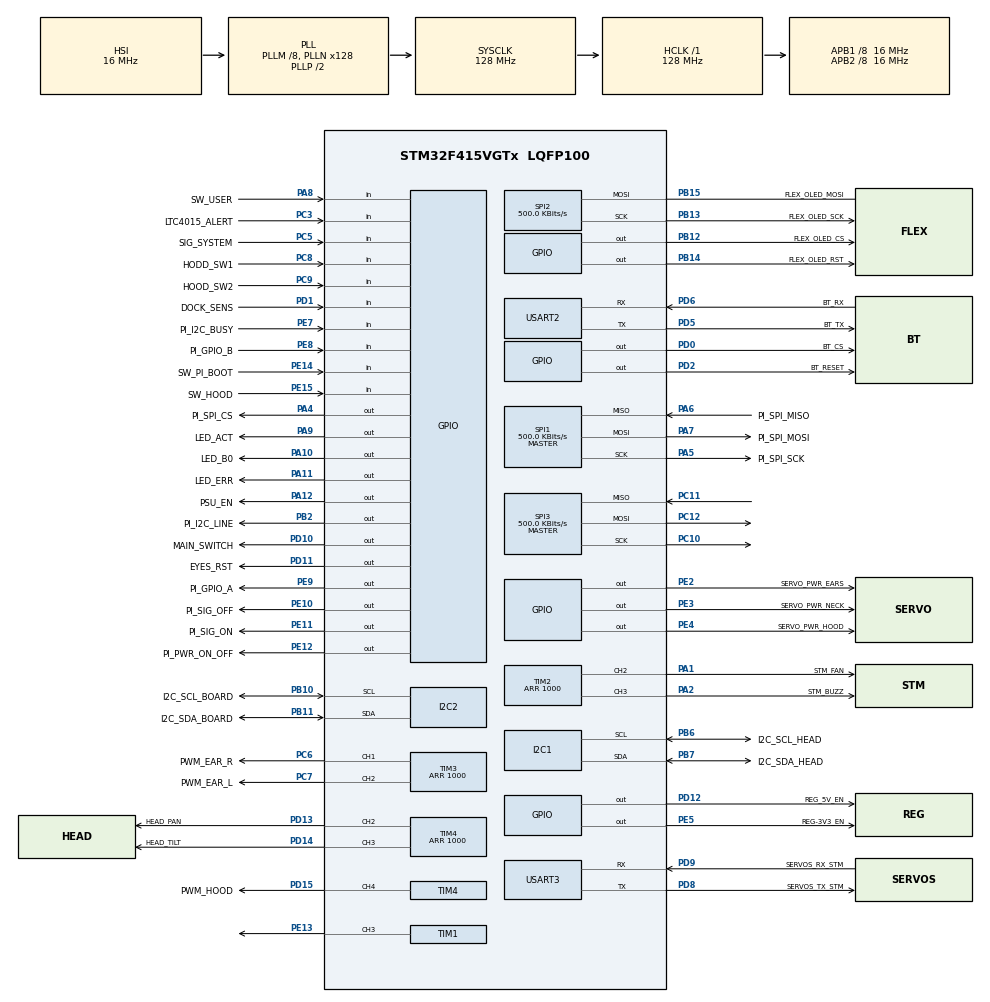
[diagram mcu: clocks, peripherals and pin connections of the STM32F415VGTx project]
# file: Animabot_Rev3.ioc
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FREERTOS.BinarySemaphores01=myBinarySem01;myBinarySem02;myBinarySem03
FREERTOS.Queues01=myQueue01,16,uint16_t,0,Dynamic,NULL,NULL
FREERTOS.Tasks01=Task_Default,0,128,StartTask_Default,Default,NULL,Dynamic,NULL,NULL;Task_Activity,-2,128,StartTask_Activity,Default,NULL,Dynamic,NULL,NULL;Task_System,0,128,StartTask_System,Default,NULL,Dynamic,NULL,NULL;Task_FlexOled,0,128,StartTask_FlexOled,Default,NULL,Dynamic,NULL,NULL;Task_PwrMngt,2,128,StartTask_PwrMngt,Default,NULL,Dynamic,NULL,NULL;Task_Sensors,2,128,StartTask_Sensors,Default,NULL,Dynamic,NULL,NULL;Task_Rpi,2,128,StartTask_Rpi,Default,NULL,Dynamic,NULL,NULL;Task_Bluetooth,0,128,StartTask_Bluetooth,Default,NULL,Dynamic,NULL,NULL;Task_Behavior,2,128,StartTask_Behavior,Default,NULL,Dynamic,NULL,NULL;Task_Kinematic,2,128,StartTask_Kinematic,Default,NULL,Dynamic,NULL,NULL
FREERTOS.configGENERATE_RUN_TIME_STATS=1
FREERTOS.configUSE_STATS_FORMATTING_FUNCTIONS=1
FREERTOS.configUSE_TICKLESS_IDLE=1
FREERTOS.configUSE_TRACE_FACILITY=1
I2C1.I2C_Mode=I2C_Fast
I2C2.I2C_Mode=I2C_Fast
Mcu.Family=STM32F4
Mcu.Name=STM32F415VGTx
Mcu.Package=LQFP100
NVIC.PriorityGroup=NVIC_PRIORITYGROUP_4
NVIC.TIM1_BRK_TIM9_IRQn=true\:0\:0\:false\:false\:true\:false\:true
PA1.GPIO_Label=STM_FAN
PA1.Signal=S_TIM2_CH2
PA10.GPIO_Label=LED_B0
PA10.GPIO_PuPd=GPIO_PULLDOWN
PA10.Signal=GPIO_Output
PA11.GPIO_Label=LED_ERR
PA11.GPIO_PuPd=GPIO_PULLDOWN
PA11.Signal=GPIO_Output
PA12.GPIO_Label=PSU_EN
PA12.GPIO_PuPd=GPIO_PULLDOWN
PA12.Signal=GPIO_Output
PA13.Mode=JTAG_5_pins
PA13.Signal=SYS_JTMS-SWDIO
PA14.Mode=JTAG_5_pins
PA14.Signal=SYS_JTCK-SWCLK
PA15.Mode=JTAG_5_pins
PA15.Signal=SYS_JTDI
PA2.GPIO_Label=STM_BUZZ
PA2.Signal=S_TIM2_CH3
PA4.GPIO_Label=PI_SPI_CS
PA4.Signal=GPIO_Output
PA5.GPIO_Label=PI_SPI_SCK
PA5.Mode=Full_Duplex_Master
PA5.Signal=SPI1_SCK
PA6.GPIO_Label=PI_SPI_MISO
PA6.Mode=Full_Duplex_Master
PA6.Signal=SPI1_MISO
PA7.GPIO_Label=PI_SPI_MOSI
PA7.Mode=Full_Duplex_Master
PA7.Signal=SPI1_MOSI
PA8.GPIO_Label=SW_USER
PA8.Signal=GPIO_Input
PA9.GPIO_Label=LED_ACT
PA9.GPIO_PuPd=GPIO_PULLDOWN
PA9.Signal=GPIO_Output
PB10.GPIO_Label=I2C_SCL_BOARD
PB10.Mode=I2C
PB10.Signal=I2C2_SCL
PB11.GPIO_Label=I2C_SDA_BOARD
PB11.Mode=I2C
PB11.Signal=I2C2_SDA
PB12.GPIO_Label=FLEX_OLED_CS
PB12.Signal=GPIO_Output
PB13.GPIO_Label=FLEX_OLED_SCK
PB13.Mode=Simplex_Bidirectional_Master
PB13.Signal=SPI2_SCK
PB14.GPIO_Label=FLEX_OLED_RST
PB14.Signal=GPIO_Output
PB15.GPIO_Label=FLEX_OLED_MOSI
PB15.Mode=Simplex_Bidirectional_Master
PB15.Signal=SPI2_MOSI
PB2.GPIO_Label=PI_I2C_LINE
PB2.Signal=GPIO_Output
PB3.Mode=JTAG_5_pins
PB3.Signal=SYS_JTDO-SWO
PB4.Mode=JTAG_5_pins
PB4.Signal=SYS_JTRST
PB6.GPIO_Label=I2C_SCL_HEAD
PB6.Mode=I2C
PB6.Signal=I2C1_SCL
PB7.GPIO_Label=I2C_SDA_HEAD
PB7.Mode=I2C
PB7.Signal=I2C1_SDA
PC10.Mode=Full_Duplex_Master
PC10.Signal=SPI3_SCK
PC11.Mode=Full_Duplex_Master
PC11.Signal=SPI3_MISO
PC12.Mode=Full_Duplex_Master
PC12.Signal=SPI3_MOSI
PC3.GPIO_Label=LTC4015_ALERT
PC3.Signal=GPIO_Input
PC5.GPIO_Label=SIG_SYSTEM
PC5.Signal=GPIO_Input
PC6.GPIO_Label=PWM_EAR_R
PC6.Signal=S_TIM3_CH1
PC7.GPIO_Label=PWM_EAR_L
PC7.Signal=S_TIM3_CH2
PC8.GPIO_Label=HODD_SW1
PC8.Signal=GPIO_Input
PC9.GPIO_Label=HOOD_SW2
PC9.Signal=GPIO_Input
PD0.GPIO_Label=BT_CS
PD0.Signal=GPIO_Output
PD1.GPIO_Label=DOCK_SENS
PD1.Signal=GPIO_Input
PD10.GPIO_Label=MAIN_SWITCH
PD10.GPIO_PuPd=GPIO_PULLDOWN
PD10.Signal=GPIO_Output
PD11.GPIO_Label=EYES_RST
PD11.Signal=GPIO_Output
PD12.GPIO_Label=REG_5V_EN
PD12.GPIO_PuPd=GPIO_PULLDOWN
PD12.Signal=GPIO_Output
PD13.GPIO_Label=HEAD_PAN
PD13.Signal=S_TIM4_CH2
PD14.GPIO_Label=HEAD_TILT
PD14.Signal=S_TIM4_CH3
PD15.GPIO_Label=PWM_HOOD
PD15.Signal=S_TIM4_CH4
PD2.GPIO_Label=BT_RESET
PD2.Signal=GPIO_Output
PD5.GPIO_Label=BT_TX
PD5.Mode=Asynchronous
PD5.Signal=USART2_TX
PD6.GPIO_Label=BT_RX
PD6.Mode=Asynchronous
PD6.Signal=USART2_RX
PD8.GPIO_Label=SERVOS_TX_STM
PD8.Mode=Asynchronous
PD8.Signal=USART3_TX
PD9.GPIO_Label=SERVOS_RX_STM
PD9.Mode=Asynchronous
PD9.Signal=USART3_RX
PE10.GPIO_Label=PI_SIG_OFF
PE10.Signal=GPIO_Output
PE11.GPIO_Label=PI_SIG_ON
PE11.Signal=GPIO_Output
PE12.GPIO_Label=PI_PWR_ON_OFF
PE12.Signal=GPIO_Output
PE13.Signal=S_TIM1_CH3
PE14.GPIO_Label=SW_PI_BOOT
PE14.Signal=GPIO_Input
PE15.GPIO_Label=SW_HOOD
PE15.Signal=GPIO_Input
PE2.GPIO_Label=SERVO_PWR_EARS
PE2.GPIO_PuPd=GPIO_PULLDOWN
PE2.Signal=GPIO_Output
PE3.GPIO_Label=SERVO_PWR_NECK
PE3.GPIO_PuPd=GPIO_PULLDOWN
PE3.Signal=GPIO_Output
PE4.GPIO_Label=SERVO_PWR_HOOD
PE4.GPIO_PuPd=GPIO_PULLDOWN
PE4.Signal=GPIO_Output
PE5.GPIO_Label=REG-3V3_EN
PE5.GPIO_PuPd=GPIO_PULLDOWN
PE5.Signal=GPIO_Output
PE7.GPIO_Label=PI_I2C_BUSY
PE7.Signal=GPIO_Input
PE8.GPIO_Label=PI_GPIO_B
PE8.Signal=GPIO_Input
PE9.GPIO_Label=PI_GPIO_A
PE9.Signal=GPIO_Output
ProjectManager.HeapSize=0x200
ProjectManager.StackSize=0x400
ProjectManager.TargetToolchain=TrueSTUDIO
RCC.48MHZClocksFreq_Value=64000000
RCC.AHBFreq_Value=128000000
RCC.APB1CLKDivider=RCC_HCLK_DIV8
RCC.APB1Freq_Value=16000000
RCC.APB1TimFreq_Value=32000000
RCC.APB2CLKDivider=RCC_HCLK_DIV8
RCC.APB2Freq_Value=16000000
RCC.APB2TimFreq_Value=32000000
RCC.CortexFreq_Value=128000000
RCC.HCLKFreq_Value=128000000
RCC.HSE_VALUE=25000000
RCC.HSI_VALUE=16000000
RCC.LSE_VALUE=32768
RCC.PLLM=8
RCC.PLLN=128
RCC.SYSCLKFreq_VALUE=128000000
RCC.SYSCLKSource=RCC_SYSCLKSOURCE_PLLCLK
RCC.VCOOutputFreq_Value=256000000
SH.S_TIM1_CH3.0=TIM1_CH3,PWM Generation3 CH3
SH.S_TIM2_CH2.0=TIM2_CH2,PWM Generation2 CH2
SH.S_TIM2_CH3.0=TIM2_CH3,PWM Generation3 CH3
SH.S_TIM3_CH1.0=TIM3_CH1,PWM Generation1 CH1
SH.S_TIM3_CH2.0=TIM3_CH2,PWM Generation2 CH2
SH.S_TIM4_CH2.0=TIM4_CH2,PWM Generation2 CH2
SH.S_TIM4_CH3.0=TIM4_CH3,PWM Generation3 CH3
SH.S_TIM4_CH4.0=TIM4_CH4,PWM Generation4 CH4
SPI1.BaudRatePrescaler=SPI_BAUDRATEPRESCALER_32
SPI1.CalculateBaudRate=500.0 KBits/s
SPI1.Direction=SPI_DIRECTION_2LINES
SPI1.Mode=SPI_MODE_MASTER
SPI1.VirtualType=VM_MASTER
SPI2.BaudRatePrescaler=SPI_BAUDRATEPRESCALER_32
SPI2.CalculateBaudRate=500.0 KBits/s
SPI2.Direction=SPI_DIRECTION_1LINE
SPI2.Mode=SPI_MODE_MASTER
SPI2.VirtualType=VM_MASTER
SPI3.BaudRatePrescaler=SPI_BAUDRATEPRESCALER_32
SPI3.CalculateBaudRate=500.0 KBits/s
SPI3.Direction=SPI_DIRECTION_2LINES
SPI3.Mode=SPI_MODE_MASTER
SPI3.VirtualType=VM_MASTER
TIM1.Channel-PWM\ Generation3\ CH3=TIM_CHANNEL_3
TIM1.Period=1000
TIM2.Channel-PWM\ Generation2\ CH2=TIM_CHANNEL_2
TIM2.Channel-PWM\ Generation3\ CH3=TIM_CHANNEL_3
TIM2.Period=1000
TIM3.Channel-PWM\ Generation1\ CH1=TIM_CHANNEL_1
TIM3.Channel-PWM\ Generation2\ CH2=TIM_CHANNEL_2
TIM3.Period=1000
TIM4.Channel-PWM\ Generation2\ CH2=TIM_CHANNEL_2
TIM4.Channel-PWM\ Generation3\ CH3=TIM_CHANNEL_3
TIM4.Channel-PWM\ Generation4\ CH4=TIM_CHANNEL_4
TIM4.Period=1000
USART2.VirtualMode=VM_ASYNC
USART3.VirtualMode=VM_ASYNC
VP_FREERTOS_VS_ENABLE.Mode=Enabled
VP_TIM1_VS_ClockSourceINT.Mode=Internal
VP_TIM2_VS_ClockSourceINT.Mode=Internal
VP_TIM3_VS_ClockSourceINT.Mode=Internal
VP_TIM4_VS_ClockSourceINT.Mode=Internal
board=Animabot_Rev3

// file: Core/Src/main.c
#include "main.h"
#include "stm32f4xx_hal.h"
#include "cmsis_os.h"
//#include "task.h"

#include "PlatformType.h"
#include "SubRoutines.h"
#include "Robot.h"

I2C_HandleTypeDef hi2c1;
I2C_HandleTypeDef hi2c2;

SPI_HandleTypeDef hspi1;
SPI_HandleTypeDef hspi2;
SPI_HandleTypeDef hspi3;

TIM_HandleTypeDef htim1;
TIM_HandleTypeDef htim2;
TIM_HandleTypeDef htim3;
TIM_HandleTypeDef htim4;

UART_HandleTypeDef huart2;
UART_HandleTypeDef huart3;

osThreadId Task_DefaultHandle;
uint32_t Task_DefaultBuffer[ 512 ];
osStaticThreadDef_t Task_DefaultControlBlock;
osThreadId Task_ActivityHandle;
uint32_t Task_ActivityBuffer[ 256 ];
osStaticThreadDef_t Task_ActivityControlBlock;
osThreadId Task_SystemHandle;
uint32_t Task_SystemBuffer[ 512 ];
osStaticThreadDef_t Task_SystemControlBlock;
osThreadId Task_FlexOledHandle;
uint32_t Task_FlexOledBuffer[ 512 ];
osStaticThreadDef_t Task_FlexOledControlBlock;
osThreadId Task_PwrMngtHandle;
uint32_t Task_PwrMngtBuffer[ 512 ];
osStaticThreadDef_t Task_PwrMngtControlBlock;
osThreadId Task_SensorsHandle;
uint32_t Task_SensorsBuffer[ 512 ];
osStaticThreadDef_t Task_SensorsControlBlock;
osThreadId Task_RpiHandle;
uint32_t Task_RpiBuffer[ 512 ];
osStaticThreadDef_t Task_RpiControlBlock;
osThreadId Task_BluetoothHandle;
uint32_t Task_BluetoothBuffer[ 256 ];
osStaticThreadDef_t Task_BluetoothControlBlock;
osThreadId Task_BehaviorHandle;
uint32_t Task_BehaviorBuffer[ 512 ];
osStaticThreadDef_t Task_BehaviorControlBlock;
osThreadId Task_KinematicHandle;
uint32_t Task_KinematicBuffer[ 512 ];
osStaticThreadDef_t Task_KinematicControlBlock;
osMessageQId myQueue01Handle;
uint8_t myQueue01Buffer[ 16 * sizeof( uint16_t ) ];
osStaticMessageQDef_t myQueue01ControlBlock;
osSemaphoreId myBinarySem01Handle;
osStaticSemaphoreDef_t myBinarySem01ControlBlock;
osSemaphoreId myBinarySem02Handle;
osStaticSemaphoreDef_t myBinarySem02ControlBlock;
osSemaphoreId myBinarySem03Handle;
osStaticSemaphoreDef_t myBinarySem03ControlBlock;

/* USER CODE BEGIN PV */
/* Private variables ---------------------------------------------------------*/

/* USER CODE END PV */

void SystemClock_Config(void);
static void MX_GPIO_Init(void);
static void MX_I2C2_Init(void);
static void MX_SPI1_Init(void);
static void MX_SPI2_Init(void);
static void MX_TIM2_Init(void);
static void MX_TIM3_Init(void);
static void MX_SPI3_Init(void);
static void MX_TIM4_Init(void);
static void MX_USART3_UART_Init(void);
static void MX_I2C1_Init(void);
static void MX_TIM1_Init(void);
static void MX_USART2_UART_Init(void);
void StartTask_Default(void const * argument);
void StartTask_Activity(void const * argument);
void StartTask_System(void const * argument);
void StartTask_FlexOled(void const * argument);
void StartTask_PwrMngt(void const * argument);
void StartTask_Sensors(void const * argument);
void StartTask_Rpi(void const * argument);
void StartTask_Bluetooth(void const * argument);
void StartTask_Behavior(void const * argument);
void StartTask_Kinematic(void const * argument);

void HAL_TIM_MspPostInit(TIM_HandleTypeDef *htim);

/*******************************************************************************************************************************************************/
/*******************************************************************************************************************************************************/

void CheckInputs(void);
void I2C_Device_Check(void);

extern void vTaskGetRunTimeStats( char *pcWriteBuffer );

Input_st Input;
Gesture_st Gesture;
Sensors_st Sensor;

DeviceStatus_enum ITG3205_Status;
DeviceStatus_enum ADXL345_Status;
DeviceStatus_enum SSD1306_Status;
DeviceStatus_enum SSD1320_Status;

I2C2_Bus_enum I2C2_Bus = I2C2_Free;

uint8_t CPUChargeBuff[8];
uint8_t Flex_OLED_Initialized = FALSE;
Flex_Oled_Menu_em Flex_Oled_Menu = Battery; //Menu displayed on Startup

uint16_t Rpi_Shutdown_ctr = 0;
uint16_t Board_Shutdown_ctr = 0;
uint16_t LowBattery_ctr = 0;

#define RPI_SPI_BUFF 8
uint8_t RPI_TxBuff[RPI_SPI_BUFF];
uint8_t RPI_RxBuff[RPI_SPI_BUFF];
uint8_t j=0;

/*******************************************************************************************************************************************************/
/*******************************************************************************************************************************************************/

int main(void)
{

	HAL_Init();

	/* Configure the system clock */
	SystemClock_Config();

	/* Initialize all configured peripherals */
	MX_GPIO_Init();
	MX_I2C2_Init();
	MX_SPI1_Init();
	MX_SPI2_Init();
	MX_TIM2_Init();
	MX_TIM3_Init();
	MX_SPI3_Init();
	MX_TIM4_Init();
	MX_USART3_UART_Init();
	MX_I2C1_Init();
	MX_TIM1_Init();
	MX_USART2_UART_Init();

  /* definition and creation of myBinarySem01 */
  osSemaphoreStaticDef(myBinarySem01, &myBinarySem01ControlBlock);
  myBinarySem01Handle = osSemaphoreCreate(osSemaphore(myBinarySem01), 1);

  /* definition and creation of myBinarySem02 */
  osSemaphoreStaticDef(myBinarySem02, &myBinarySem02ControlBlock);
  myBinarySem02Handle = osSemaphoreCreate(osSemaphore(myBinarySem02), 1);

  /* definition and creation of myBinarySem03 */
  osSemaphoreStaticDef(myBinarySem03, &myBinarySem03ControlBlock);
  myBinarySem03Handle = osSemaphoreCreate(osSemaphore(myBinarySem03), 1);

  /* Create the thread(s) */
  /* definition and creation of Task_Default */
  osThreadStaticDef(Task_Default, StartTask_Default, osPriorityNormal, 0, 512, Task_DefaultBuffer, &Task_DefaultControlBlock);
  Task_DefaultHandle = osThreadCreate(osThread(Task_Default), NULL);

  /* definition and creation of Task_Activity */
  osThreadStaticDef(Task_Activity, StartTask_Activity, osPriorityLow, 0, 256, Task_ActivityBuffer, &Task_ActivityControlBlock);
  Task_ActivityHandle = osThreadCreate(osThread(Task_Activity), NULL);

  /* definition and creation of Task_System */
  osThreadStaticDef(Task_System, StartTask_System, osPriorityNormal, 0, 512, Task_SystemBuffer, &Task_SystemControlBlock);
  Task_SystemHandle = osThreadCreate(osThread(Task_System), NULL);

  /* definition and creation of Task_FlexOled */
  osThreadStaticDef(Task_FlexOled, StartTask_FlexOled, osPriorityNormal, 0, 512, Task_FlexOledBuffer, &Task_FlexOledControlBlock);
  Task_FlexOledHandle = osThreadCreate(osThread(Task_FlexOled), NULL);

  /* definition and creation of Task_PwrMngt */
  osThreadStaticDef(Task_PwrMngt, StartTask_PwrMngt, osPriorityHigh, 0, 512, Task_PwrMngtBuffer, &Task_PwrMngtControlBlock);
  Task_PwrMngtHandle = osThreadCreate(osThread(Task_PwrMngt), NULL);

  /* definition and creation of Task_Sensors */
  osThreadStaticDef(Task_Sensors, StartTask_Sensors, osPriorityHigh, 0, 512, Task_SensorsBuffer, &Task_SensorsControlBlock);
  Task_SensorsHandle = osThreadCreate(osThread(Task_Sensors), NULL);

  /* definition and creation of Task_Rpi */
  osThreadStaticDef(Task_Rpi, StartTask_Rpi, osPriorityHigh, 0, 512, Task_RpiBuffer, &Task_RpiControlBlock);
  Task_RpiHandle = osThreadCreate(osThread(Task_Rpi), NULL);

  /* definition and creation of Task_Bluetooth */
  osThreadStaticDef(Task_Bluetooth, StartTask_Bluetooth, osPriorityNormal, 0, 256, Task_BluetoothBuffer, &Task_BluetoothControlBlock);
  Task_BluetoothHandle = osThreadCreate(osThread(Task_Bluetooth), NULL);

  /* definition and creation of Task_Behavior */
  osThreadStaticDef(Task_Behavior, StartTask_Behavior, osPriorityHigh, 0, 512, Task_BehaviorBuffer, &Task_BehaviorControlBlock);
  Task_BehaviorHandle = osThreadCreate(osThread(Task_Behavior), NULL);

  /* definition and creation of Task_Kinematic */
  osThreadStaticDef(Task_Kinematic, StartTask_Kinematic, osPriorityHigh, 0, 512, Task_KinematicBuffer, &Task_KinematicControlBlock);
  Task_KinematicHandle = osThreadCreate(osThread(Task_Kinematic), NULL);

	/* definition and creation of myQueue01 */
  osMessageQStaticDef(myQueue01, 16, uint16_t, myQueue01Buffer, &myQueue01ControlBlock);
	myQueue01Handle = osMessageCreate(osMessageQ(myQueue01), NULL);
	osKernelStart();

	while (1)
	{

	}

}

/*******************************************************************************************************************************************************/
/*******************************************************************************************************************************************************/
/*******************************************************************************************************************************************************/
/*******************************************************************************************************************************************************/
/*******************************************************************************************************************************************************/

void SystemClock_Config(void)
{

  RCC_OscInitTypeDef RCC_OscInitStruct;
  RCC_ClkInitTypeDef RCC_ClkInitStruct;

    /**Configure the main internal regulator output voltage
    */
  __HAL_RCC_PWR_CLK_ENABLE();

  __HAL_PWR_VOLTAGESCALING_CONFIG(PWR_REGULATOR_VOLTAGE_SCALE1);

    /**Initializes the CPU, AHB and APB busses clocks
    */
  RCC_OscInitStruct.OscillatorType = RCC_OSCILLATORTYPE_HSI;
  RCC_OscInitStruct.HSIState = RCC_HSI_ON;
  RCC_OscInitStruct.HSICalibrationValue = 16;
  RCC_OscInitStruct.PLL.PLLState = RCC_PLL_ON;
  RCC_OscInitStruct.PLL.PLLSource = RCC_PLLSOURCE_HSI;
  RCC_OscInitStruct.PLL.PLLM = 8;
  RCC_OscInitStruct.PLL.PLLN = 128;
  RCC_OscInitStruct.PLL.PLLP = RCC_PLLP_DIV2;
  RCC_OscInitStruct.PLL.PLLQ = 4;
  if (HAL_RCC_OscConfig(&RCC_OscInitStruct) != HAL_OK)
  {
    _Error_Handler(__FILE__, __LINE__);
  }

    /**Initializes the CPU, AHB and APB busses clocks
    */
  RCC_ClkInitStruct.ClockType = RCC_CLOCKTYPE_HCLK|RCC_CLOCKTYPE_SYSCLK|RCC_CLOCKTYPE_PCLK1|RCC_CLOCKTYPE_PCLK2;
  RCC_ClkInitStruct.SYSCLKSource = RCC_SYSCLKSOURCE_PLLCLK;
  RCC_ClkInitStruct.AHBCLKDivider = RCC_SYSCLK_DIV1;
  RCC_ClkInitStruct.APB1CLKDivider = RCC_HCLK_DIV8;
  RCC_ClkInitStruct.APB2CLKDivider = RCC_HCLK_DIV8;

  if (HAL_RCC_ClockConfig(&RCC_ClkInitStruct, FLASH_LATENCY_4) != HAL_OK)
  {
    _Error_Handler(__FILE__, __LINE__);
  }

    /**Configure the Systick interrupt time
    */
  HAL_SYSTICK_Config(HAL_RCC_GetHCLKFreq()/1000);

    /**Configure the Systick
    */
  HAL_SYSTICK_CLKSourceConfig(SYSTICK_CLKSOURCE_HCLK);

  /* SysTick_IRQn interrupt configuration */
  HAL_NVIC_SetPriority(SysTick_IRQn, 15, 0);
}

/* I2C1 init function - (SSD1306) */
static void MX_I2C1_Init(void)
{

  hi2c1.Instance = I2C1;
  hi2c1.Init.ClockSpeed = 400000;
  hi2c1.Init.DutyCycle = I2C_DUTYCYCLE_16_9;
  hi2c1.Init.OwnAddress1 = 0;
  hi2c1.Init.AddressingMode = I2C_ADDRESSINGMODE_7BIT;
  hi2c1.Init.DualAddressMode = I2C_DUALADDRESS_DISABLE;
  hi2c1.Init.OwnAddress2 = 0;
  hi2c1.Init.GeneralCallMode = I2C_GENERALCALL_DISABLE;
  hi2c1.Init.NoStretchMode = I2C_NOSTRETCH_DISABLE;
  if (HAL_I2C_Init(&hi2c1) != HAL_OK)
  {
    _Error_Handler(__FILE__, __LINE__);
  }

}

/* I2C2 init function - (All Sensors) */
static void MX_I2C2_Init(void)
{

  hi2c2.Instance = I2C2;
  hi2c2.Init.ClockSpeed = 200000;
  hi2c2.Init.DutyCycle = I2C_DUTYCYCLE_2;
  hi2c2.Init.OwnAddress1 = 0;
  hi2c2.Init.AddressingMode = I2C_ADDRESSINGMODE_7BIT;
  hi2c2.Init.DualAddressMode = I2C_DUALADDRESS_DISABLE;
  hi2c2.Init.OwnAddress2 = 0;
  hi2c2.Init.GeneralCallMode = I2C_GENERALCALL_DISABLE;
  hi2c2.Init.NoStretchMode = I2C_NOSTRETCH_DISABLE;
  if (HAL_I2C_Init(&hi2c2) != HAL_OK)
  {
    _Error_Handler(__FILE__, __LINE__);
  }

}

/* SPI1 init function - (Raspberry Pi) */
static void MX_SPI1_Init(void)
{

  /* SPI1 parameter configuration*/
  hspi1.Instance = SPI1;
  hspi1.Init.Mode = SPI_MODE_SLAVE;
  hspi1.Init.Direction = SPI_DIRECTION_2LINES;
  hspi1.Init.DataSize = SPI_DATASIZE_8BIT;
  hspi1.Init.CLKPolarity = SPI_POLARITY_LOW;
  hspi1.Init.CLKPhase = SPI_PHASE_1EDGE;
  hspi1.Init.NSS = SPI_NSS_HARD_INPUT;
  hspi1.Init.FirstBit = SPI_FIRSTBIT_MSB;
  hspi1.Init.TIMode = SPI_TIMODE_DISABLE;
  hspi1.Init.CRCCalculation = SPI_CRCCALCULATION_DISABLE;
  hspi1.Init.CRCPolynomial = 10;
  if (HAL_SPI_Init(&hspi1) != HAL_OK)
  {
    _Error_Handler(__FILE__, __LINE__);
  }

}

/* SPI2 init function - (Flex OLED) */
static void MX_SPI2_Init(void)
{

  /* SPI2 parameter configuration*/
  hspi2.Instance = SPI2;
  hspi2.Init.Mode = SPI_MODE_MASTER;
  hspi2.Init.Direction = SPI_DIRECTION_1LINE;
  hspi2.Init.DataSize = SPI_DATASIZE_8BIT;
  hspi2.Init.CLKPolarity = SPI_POLARITY_LOW;
  hspi2.Init.CLKPhase = SPI_PHASE_1EDGE;
  hspi2.Init.NSS = SPI_NSS_SOFT;
  hspi2.Init.BaudRatePrescaler = SPI_BAUDRATEPRESCALER_32;
  hspi2.Init.FirstBit = SPI_FIRSTBIT_MSB;
  hspi2.Init.TIMode = SPI_TIMODE_DISABLE;
  hspi2.Init.CRCCalculation = SPI_CRCCALCULATION_DISABLE;
  hspi2.Init.CRCPolynomial = 10;
  if (HAL_SPI_Init(&hspi2) != HAL_OK)
  {
    _Error_Handler(__FILE__, __LINE__);
  }

}

/* SPI3 init function - (Bluetooth Module) */
static void MX_SPI3_Init(void)
{

  /* SPI3 parameter configuration*/
  hspi3.Instance = SPI3;
  hspi3.Init.Mode = SPI_MODE_MASTER;
  hspi3.Init.Direction = SPI_DIRECTION_2LINES;
  hspi3.Init.DataSize = SPI_DATASIZE_8BIT;
  hspi3.Init.CLKPolarity = SPI_POLARITY_LOW;
  hspi3.Init.CLKPhase = SPI_PHASE_1EDGE;
  hspi3.Init.NSS = SPI_NSS_SOFT;
  hspi3.Init.BaudRatePrescaler = SPI_BAUDRATEPRESCALER_32;
  hspi3.Init.FirstBit = SPI_FIRSTBIT_MSB;
  hspi3.Init.TIMode = SPI_TIMODE_DISABLE;
  hspi3.Init.CRCCalculation = SPI_CRCCALCULATION_DISABLE;
  hspi3.Init.CRCPolynomial = 10;
  if (HAL_SPI_Init(&hspi3) != HAL_OK)
  {
    _Error_Handler(__FILE__, __LINE__);
  }

}

/* TIM1 init function */
static void MX_TIM1_Init(void)
{

  TIM_ClockConfigTypeDef sClockSourceConfig;
  TIM_MasterConfigTypeDef sMasterConfig;
  TIM_OC_InitTypeDef sConfigOC;
  TIM_BreakDeadTimeConfigTypeDef sBreakDeadTimeConfig;

  htim1.Instance = TIM1;
  htim1.Init.Prescaler = 0;
  htim1.Init.CounterMode = TIM_COUNTERMODE_UP;
  htim1.Init.Period = 1000;
  htim1.Init.ClockDivision = TIM_CLOCKDIVISION_DIV1;
  htim1.Init.RepetitionCounter = 0;
  if (HAL_TIM_Base_Init(&htim1) != HAL_OK)
  {
    _Error_Handler(__FILE__, __LINE__);
  }

  sClockSourceConfig.ClockSource = TIM_CLOCKSOURCE_INTERNAL;
  if (HAL_TIM_ConfigClockSource(&htim1, &sClockSourceConfig) != HAL_OK)
  {
    _Error_Handler(__FILE__, __LINE__);
  }

  if (HAL_TIM_PWM_Init(&htim1) != HAL_OK)
  {
    _Error_Handler(__FILE__, __LINE__);
  }

  sMasterConfig.MasterOutputTrigger = TIM_TRGO_RESET;
  sMasterConfig.MasterSlaveMode = TIM_MASTERSLAVEMODE_DISABLE;
  if (HAL_TIMEx_MasterConfigSynchronization(&htim1, &sMasterConfig) != HAL_OK)
  {
    _Error_Handler(__FILE__, __LINE__);
  }

  sConfigOC.OCMode = TIM_OCMODE_PWM1;
  sConfigOC.Pulse = 0;
  sConfigOC.OCPolarity = TIM_OCPOLARITY_HIGH;
  sConfigOC.OCNPolarity = TIM_OCNPOLARITY_HIGH;
  sConfigOC.OCFastMode = TIM_OCFAST_DISABLE;
  sConfigOC.OCIdleState = TIM_OCIDLESTATE_RESET;
  sConfigOC.OCNIdleState = TIM_OCNIDLESTATE_RESET;
  if (HAL_TIM_PWM_ConfigChannel(&htim1, &sConfigOC, TIM_CHANNEL_3) != HAL_OK)
  {
    _Error_Handler(__FILE__, __LINE__);
  }

  sBreakDeadTimeConfig.OffStateRunMode = TIM_OSSR_DISABLE;
  sBreakDeadTimeConfig.OffStateIDLEMode = TIM_OSSI_DISABLE;
  sBreakDeadTimeConfig.LockLevel = TIM_LOCKLEVEL_OFF;
  sBreakDeadTimeConfig.DeadTime = 0;
  sBreakDeadTimeConfig.BreakState = TIM_BREAK_DISABLE;
  sBreakDeadTimeConfig.BreakPolarity = TIM_BREAKPOLARITY_HIGH;
  sBreakDeadTimeConfig.AutomaticOutput = TIM_AUTOMATICOUTPUT_DISABLE;
  if (HAL_TIMEx_ConfigBreakDeadTime(&htim1, &sBreakDeadTimeConfig) != HAL_OK)
  {
    _Error_Handler(__FILE__, __LINE__);
  }

  HAL_TIM_MspPostInit(&htim1);

}

/* TIM2 init function */
static void MX_TIM2_Init(void)
{

  TIM_ClockConfigTypeDef sClockSourceConfig;
  TIM_MasterConfigTypeDef sMasterConfig;
  TIM_OC_InitTypeDef sConfigOC;

  htim2.Instance = TIM2;
  htim2.Init.Prescaler = 0;
  htim2.Init.CounterMode = TIM_COUNTERMODE_UP;
  htim2.Init.Period = 1000;
  htim2.Init.ClockDivision = TIM_CLOCKDIVISION_DIV1;
  if (HAL_TIM_Base_Init(&htim2) != HAL_OK)
  {
    _Error_Handler(__FILE__, __LINE__);
  }

  sClockSourceConfig.ClockSource = TIM_CLOCKSOURCE_INTERNAL;
  if (HAL_TIM_ConfigClockSource(&htim2, &sClockSourceConfig) != HAL_OK)
  {
    _Error_Handler(__FILE__, __LINE__);
  }

  if (HAL_TIM_PWM_Init(&htim2) != HAL_OK)
  {
    _Error_Handler(__FILE__, __LINE__);
  }

  sMasterConfig.MasterOutputTrigger = TIM_TRGO_RESET;
  sMasterConfig.MasterSlaveMode = TIM_MASTERSLAVEMODE_DISABLE;
  if (HAL_TIMEx_MasterConfigSynchronization(&htim2, &sMasterConfig) != HAL_OK)
  {
    _Error_Handler(__FILE__, __LINE__);
  }

  sConfigOC.OCMode = TIM_OCMODE_PWM1;
  sConfigOC.Pulse = 0;
  sConfigOC.OCPolarity = TIM_OCPOLARITY_HIGH;
  sConfigOC.OCFastMode = TIM_OCFAST_DISABLE;
  if (HAL_TIM_PWM_ConfigChannel(&htim2, &sConfigOC, TIM_CHANNEL_2) != HAL_OK)
  {
    _Error_Handler(__FILE__, __LINE__);
  }

  if (HAL_TIM_PWM_ConfigChannel(&htim2, &sConfigOC, TIM_CHANNEL_3) != HAL_OK)
  {
    _Error_Handler(__FILE__, __LINE__);
  }

  HAL_TIM_MspPostInit(&htim2);

}

/* TIM3 init function */
static void MX_TIM3_Init(void)
{

  TIM_ClockConfigTypeDef sClockSourceConfig;
  TIM_MasterConfigTypeDef sMasterConfig;
  TIM_OC_InitTypeDef sConfigOC;

  htim3.Instance = TIM3;
  htim3.Init.Prescaler = 32; //1MHz -> Cnt increases by 1000000 every 1sec -> 1=1µs so 1.5ms = 1500µs | old=32MHz/640000 = 50Hz - 640
  htim3.Init.CounterMode = TIM_COUNTERMODE_UP;
  htim3.Init.Period = 19999;
  htim3.Init.ClockDivision = TIM_CLOCKDIVISION_DIV1;
  if (HAL_TIM_Base_Init(&htim3) != HAL_OK)
  {
    _Error_Handler(__FILE__, __LINE__);
  }

  sClockSourceConfig.ClockSource = TIM_CLOCKSOURCE_INTERNAL;
  if (HAL_TIM_ConfigClockSource(&htim3, &sClockSourceConfig) != HAL_OK)
  {
    _Error_Handler(__FILE__, __LINE__);
  }

  if (HAL_TIM_PWM_Init(&htim3) != HAL_OK)
  {
    _Error_Handler(__FILE__, __LINE__);
  }

  sMasterConfig.MasterOutputTrigger = TIM_TRGO_RESET;
  sMasterConfig.MasterSlaveMode = TIM_MASTERSLAVEMODE_DISABLE;
  if (HAL_TIMEx_MasterConfigSynchronization(&htim3, &sMasterConfig) != HAL_OK)
  {
    _Error_Handler(__FILE__, __LINE__);
  }

  sConfigOC.OCMode = TIM_OCMODE_PWM1;
  sConfigOC.Pulse = 0;
  sConfigOC.OCPolarity = TIM_OCPOLARITY_HIGH;
  sConfigOC.OCFastMode = TIM_OCFAST_DISABLE;
  if (HAL_TIM_PWM_ConfigChannel(&htim3, &sConfigOC, TIM_CHANNEL_1) != HAL_OK)
  {
    _Error_Handler(__FILE__, __LINE__);
  }

  if (HAL_TIM_PWM_ConfigChannel(&htim3, &sConfigOC, TIM_CHANNEL_2) != HAL_OK)
  {
    _Error_Handler(__FILE__, __LINE__);
  }

  HAL_TIM_MspPostInit(&htim3);

}

/* TIM4 init function */
static void MX_TIM4_Init(void)
{

  TIM_ClockConfigTypeDef sClockSourceConfig;
  TIM_MasterConfigTypeDef sMasterConfig;
  TIM_OC_InitTypeDef sConfigOC;

  htim4.Instance = TIM4;
  htim4.Init.Prescaler = 32; //640; // 32MHz/333Hz = 96096
  htim4.Init.CounterMode = TIM_COUNTERMODE_UP;
  htim4.Init.Period = 3000;
  htim4.Init.ClockDivision = TIM_CLOCKDIVISION_DIV1;
  if (HAL_TIM_Base_Init(&htim4) != HAL_OK)
  {
    _Error_Handler(__FILE__, __LINE__);
  }

  sClockSourceConfig.ClockSource = TIM_CLOCKSOURCE_INTERNAL;
  if (HAL_TIM_ConfigClockSource(&htim4, &sClockSourceConfig) != HAL_OK)
  {
    _Error_Handler(__FILE__, __LINE__);
  }

  if (HAL_TIM_PWM_Init(&htim4) != HAL_OK)
  {
    _Error_Handler(__FILE__, __LINE__);
  }

  sMasterConfig.MasterOutputTrigger = TIM_TRGO_RESET;
  sMasterConfig.MasterSlaveMode = TIM_MASTERSLAVEMODE_DISABLE;
  if (HAL_TIMEx_MasterConfigSynchronization(&htim4, &sMasterConfig) != HAL_OK)
  {
    _Error_Handler(__FILE__, __LINE__);
  }

  sConfigOC.OCMode = TIM_OCMODE_PWM1;
  sConfigOC.Pulse = 0;
  sConfigOC.OCPolarity = TIM_OCPOLARITY_HIGH;
  sConfigOC.OCFastMode = TIM_OCFAST_DISABLE;
  if (HAL_TIM_PWM_ConfigChannel(&htim4, &sConfigOC, TIM_CHANNEL_2) != HAL_OK)
  {
    _Error_Handler(__FILE__, __LINE__);
  }

  if (HAL_TIM_PWM_ConfigChannel(&htim4, &sConfigOC, TIM_CHANNEL_3) != HAL_OK)
  {
    _Error_Handler(__FILE__, __LINE__);
  }

  if (HAL_TIM_PWM_ConfigChannel(&htim4, &sConfigOC, TIM_CHANNEL_4) != HAL_OK)
  {
    _Error_Handler(__FILE__, __LINE__);
  }

  HAL_TIM_MspPostInit(&htim4);

}

/* USART2 init function */
static void MX_USART2_UART_Init(void)
{

  huart2.Instance = USART2;
  huart2.Init.BaudRate = 115200;
  huart2.Init.WordLength = UART_WORDLENGTH_8B;
  huart2.Init.StopBits = UART_STOPBITS_1;
  huart2.Init.Parity = UART_PARITY_NONE;
  huart2.Init.Mode = UART_MODE_TX_RX;
  huart2.Init.HwFlowCtl = UART_HWCONTROL_NONE;
  huart2.Init.OverSampling = UART_OVERSAMPLING_16;
  if (HAL_UART_Init(&huart2) != HAL_OK)
  {
    _Error_Handler(__FILE__, __LINE__);
  }

}

/* USART3 init function */
static void MX_USART3_UART_Init(void)
{

  huart3.Instance = USART3;
  huart3.Init.BaudRate = 115200;
  huart3.Init.WordLength = UART_WORDLENGTH_8B;
  huart3.Init.StopBits = UART_STOPBITS_1;
  huart3.Init.Parity = UART_PARITY_NONE;
  huart3.Init.Mode = UART_MODE_TX_RX;
  huart3.Init.HwFlowCtl = UART_HWCONTROL_NONE;
  huart3.Init.OverSampling = UART_OVERSAMPLING_16;
  if (HAL_UART_Init(&huart3) != HAL_OK)
  {
    _Error_Handler(__FILE__, __LINE__);
  }

}

/** Configure pins as
        * Analog
        * Input
        * Output
        * EVENT_OUT
        * EXTI
*/
static void MX_GPIO_Init(void)
{

	GPIO_InitTypeDef GPIO_InitStruct;

	/* GPIO Ports Clock Enable */
	__HAL_RCC_GPIOE_CLK_ENABLE();
	__HAL_RCC_GPIOC_CLK_ENABLE();
	__HAL_RCC_GPIOA_CLK_ENABLE();
	__HAL_RCC_GPIOB_CLK_ENABLE();
	__HAL_RCC_GPIOD_CLK_ENABLE();

	/*Configure GPIO pin Output Level */
	HAL_GPIO_WritePin(GPIOE, SERVO_PWR_EARS_Pin|SERVO_PWR_NECK_Pin|SERVO_PWR_HOOD_Pin|REG_3V3_EN_Pin
						  |PI_GPIO_A_Pin|PI_SIG_OFF_Pin|PI_SIG_ON_Pin|PI_PWR_ON_OFF_Pin, GPIO_PIN_RESET);

  /*Configure GPIO pin Output Level */
  HAL_GPIO_WritePin(GPIOB, PI_I2C_LINE_Pin|FLEX_OLED_CS_Pin|FLEX_OLED_RST_Pin, GPIO_PIN_RESET);

	/*Configure GPIO pin Output Level */
	HAL_GPIO_WritePin(GPIOD, MAIN_SWITCH_Pin|EYES_RST_Pin|REG_5V_EN_Pin|BT_CS_Pin
						  |BT_RESET_Pin, GPIO_PIN_RESET);

  /*Configure GPIO pin Output Level */
  HAL_GPIO_WritePin(GPIOA, LED_ACT_Pin|LED_B0_Pin|LED_ERR_Pin|PSU_EN_Pin, GPIO_PIN_RESET);
	/*Configure GPIO pins : SERVO_PWR_EARS_Pin SERVO_PWR_NECK_Pin SERVO_PWR_HOOD_Pin REG_3V3_EN_Pin */
	GPIO_InitStruct.Pin = SERVO_PWR_EARS_Pin|SERVO_PWR_NECK_Pin|SERVO_PWR_HOOD_Pin|REG_3V3_EN_Pin;
	GPIO_InitStruct.Mode = GPIO_MODE_OUTPUT_PP;
	GPIO_InitStruct.Pull = GPIO_PULLDOWN;
	GPIO_InitStruct.Speed = GPIO_SPEED_FREQ_LOW;
	HAL_GPIO_Init(GPIOE, &GPIO_InitStruct);

	/*Configure GPIO pins : LTC4015_ALERT_Pin SIG_SYSTEM_Pin HODD_SW1_Pin HOOD_SW2_Pin */
	GPIO_InitStruct.Pin = LTC4015_ALERT_Pin|SIG_SYSTEM_Pin|HODD_SW1_Pin|HOOD_SW2_Pin;
	GPIO_InitStruct.Mode = GPIO_MODE_INPUT;
	GPIO_InitStruct.Pull = GPIO_NOPULL;
	HAL_GPIO_Init(GPIOC, &GPIO_InitStruct);

	/*Configure GPIO pins : PI_I2C_LINE_Pin FLEX_OLED_CS_Pin FLEX_OLED_RST_Pin */
	GPIO_InitStruct.Pin = PI_I2C_LINE_Pin|FLEX_OLED_CS_Pin|FLEX_OLED_RST_Pin;
	GPIO_InitStruct.Mode = GPIO_MODE_OUTPUT_PP;
	GPIO_InitStruct.Pull = GPIO_NOPULL;
	GPIO_InitStruct.Speed = GPIO_SPEED_FREQ_LOW;
	HAL_GPIO_Init(GPIOB, &GPIO_InitStruct);

	/*Configure GPIO pins : PI_I2C_BUSY_Pin PI_GPIO_B_Pin SW_PI_BOOT_Pin SW_HOOD_Pin */
	GPIO_InitStruct.Pin = PI_I2C_BUSY_Pin|PI_GPIO_B_Pin|SW_PI_BOOT_Pin|SW_HOOD_Pin;
	GPIO_InitStruct.Mode = GPIO_MODE_INPUT;
	GPIO_InitStruct.Pull = GPIO_NOPULL;
	HAL_GPIO_Init(GPIOE, &GPIO_InitStruct);

	/*Configure GPIO pins : PI_GPIO_A_Pin PI_SIG_OFF_Pin PI_SIG_ON_Pin PI_PWR_ON_OFF_Pin */
	GPIO_InitStruct.Pin = PI_GPIO_A_Pin|PI_SIG_OFF_Pin|PI_SIG_ON_Pin|PI_PWR_ON_OFF_Pin;
	GPIO_InitStruct.Mode = GPIO_MODE_OUTPUT_PP;
	GPIO_InitStruct.Pull = GPIO_NOPULL;
	GPIO_InitStruct.Speed = GPIO_SPEED_FREQ_LOW;
	HAL_GPIO_Init(GPIOE, &GPIO_InitStruct);

	/*Configure GPIO pins : MAIN_SWITCH_Pin REG_5V_EN_Pin */
	GPIO_InitStruct.Pin = MAIN_SWITCH_Pin|REG_5V_EN_Pin;
	GPIO_InitStruct.Mode = GPIO_MODE_OUTPUT_PP;
	GPIO_InitStruct.Pull = GPIO_PULLDOWN;
	GPIO_InitStruct.Speed = GPIO_SPEED_FREQ_LOW;
	HAL_GPIO_Init(GPIOD, &GPIO_InitStruct);

	/*Configure GPIO pins : EYES_RST_Pin BT_CS_Pin BT_RESET_Pin */
	GPIO_InitStruct.Pin = EYES_RST_Pin|BT_CS_Pin|BT_RESET_Pin;
	GPIO_InitStruct.Mode = GPIO_MODE_OUTPUT_PP;
	GPIO_InitStruct.Pull = GPIO_NOPULL;
	GPIO_InitStruct.Speed = GPIO_SPEED_FREQ_LOW;
	HAL_GPIO_Init(GPIOD, &GPIO_InitStruct);

	/*Configure GPIO pin : SW_USER_Pin */
	GPIO_InitStruct.Pin = SW_USER_Pin;
	GPIO_InitStruct.Mode = GPIO_MODE_INPUT;
	GPIO_InitStruct.Pull = GPIO_NOPULL;
	HAL_GPIO_Init(SW_USER_GPIO_Port, &GPIO_InitStruct);

	/*Configure GPIO pins : LED_ACT_Pin LED_B0_Pin LED_ERR_Pin PSU_EN_Pin */
	GPIO_InitStruct.Pin = LED_ACT_Pin|LED_B0_Pin|LED_ERR_Pin|PSU_EN_Pin;
	GPIO_InitStruct.Mode = GPIO_MODE_OUTPUT_PP;
	GPIO_InitStruct.Pull = GPIO_PULLDOWN;
	GPIO_InitStruct.Speed = GPIO_SPEED_FREQ_LOW;
	HAL_GPIO_Init(GPIOA, &GPIO_InitStruct);

	/*Configure GPIO pin : DOCK_SENS_Pin */
	GPIO_InitStruct.Pin = DOCK_SENS_Pin;
	GPIO_InitStruct.Mode = GPIO_MODE_INPUT;
	GPIO_InitStruct.Pull = GPIO_NOPULL;
	HAL_GPIO_Init(DOCK_SENS_GPIO_Port, &GPIO_InitStruct);

	/* Flex OLED Display */
    GPIO_InitStruct.Pin = FLEX_OLED_SCK_Pin|FLEX_OLED_MOSI_Pin;
    GPIO_InitStruct.Mode = GPIO_MODE_AF_PP;
    GPIO_InitStruct.Pull = GPIO_NOPULL;
    GPIO_InitStruct.Speed = GPIO_SPEED_FREQ_VERY_HIGH;
    GPIO_InitStruct.Alternate = GPIO_AF5_SPI2;
    HAL_GPIO_Init(GPIOB, &GPIO_InitStruct);
}

/*******************************************************************************************************************************************************/
/*******************************************************************************************************************************************************/
/*******************************************************************************************************************************************************/
/*******************************************************************************************************************************************************/
/*******************************************************************************************************************************************************/

void StartTask_PwrMngt(void const * argument)
{
	LTC4015_ChargerState chargerState = 0x0000;
	LTC4015_ChargeStatus chargeStatus = 0x0000;
	LTC4015_LimitAlerts limitAlerts = 0x0000;
	LTC4015_ChargeStateAlerts stateAlerts = 0x0000;
	LTC4015_ChargeStatusAlerts statusAlerts = 0x0000;
	LTC4015_SystemStatus systemStatus = 0x0000;
	LTC4015_InitValues();

	set_PSU_3V3(ON);
	set_MAIN_SWITCH(ON);
	osDelay(250);
	set_PSU_5V(ON);
	osDelay(250);
	set_PSU_DRS0101(ON);
	BIP_0();

	Robot.RPiState = RPi_OFF;

	for(;;)
	{
		RPi_PwrMngt();
		Board_PwrMngt();

		LTC4015_GetChargerState(&chargerState);
		LTC4015_GetChargeStatus(&chargeStatus);
		LTC4015_GetPowerVal();

		if( ((Charger.Power.BatVoltage > 7) && (Charger.Power.BatVoltage < 9.50)) && (Input.SIG_SYS == GPIO_PIN_SET) )
		{
			set_LED_ERR(ON);
			LowBattery_ctr ++;

			if(LowBattery_ctr>=250)
			{
				LowBattery_ctr = 0;
				BIP_4();
			}
		}

		PWM_FAN = (uint16_t)(Sensor.TempPSU*15);
		Sensor.Fan_Speed = PWM_FAN;

		osDelay(100);
	}

}

void StartTask_System(void const * argument)
{

	HAL_TIM_PWM_Start(&htim2, TIM_CHANNEL_2);	// FAN
	HAL_TIM_PWM_Start(&htim1, TIM_CHANNEL_3);	// Rpi LED
	HAL_TIM_PWM_Start(&htim2, TIM_CHANNEL_3);	// BUZZ

	SSD1306_Init();
	LTC4015_Init();
	EarsServos_Init();
	NeckServos_Init();
	//HoodServos_Init();

	PWM_LED_PI = 0;
	PWM_FAN = 500;
	PWM_BUZZ = 0;

	for(;;)
	{
		CheckInputs();
		osDelay(100);
	}

}

void StartTask_Activity(void const * argument)
{
	for(;;)
	{
		set_LED_ACT(ON);
		osDelay(75);
		set_LED_ACT(OFF);
		osDelay(150);
		set_LED_ACT(ON);
		osDelay(75);
		set_LED_ACT(OFF);
		osDelay(1000);
	}
}

void StartTask_Default(void const * argument)
{
	uint16_t RegVAl;
	uint16_t IR_Val;
	uint16_t ChargerState = 0xFF;
	float x, y, z;
	uint8_t i;

	osDelay(250);

	for(;;)
	{

		if(Input.SW_OLED_MENU == GPIO_PIN_SET)
		{
			set_LED_B0(ON);

			Flex_Oled_Menu ++;
			if(Flex_Oled_Menu > 3) { Flex_Oled_Menu = 0; }
			Flex_OLED_clearDisplay(CLEAR_ALL);
			Flex_OLED_Update();
			osDelay(100);
		}
		else
		{
			set_LED_B0(OFF);
		}

		if(Input.SW1 == GPIO_PIN_SET)
		{
/*
			RPI_RxBuff[0] = 0x01;
			RPI_RxBuff[1] = 0x42;
			RPI_RxBuff[2] = 0x01;
			RPI_RxBuff[3] = 140;
			RPI_RxBuff[4] = 0x00;
			RPI_RxBuff[5] = 23;
			RPI_RxBuff[6] = 14;
			RPI_RxBuff[7] = 0x00;

			Tracking_ArUco(RPI_RxBuff[1], RPI_RxBuff[2], RPI_RxBuff[3], RPI_RxBuff[4], RPI_RxBuff[5], RPI_RxBuff[6]);
*/
			x = Robot.LegPos.Init_X;
			y = Robot.LegPos.Init_Y;
			z = Robot.LegPos.Init_Z;

			for(z = Robot.LegPos.Init_Z ; z >= -80 ; z-=5 )
			{
				IK_SingleLegDrive(0, x, y, z, 20);
				IK_SingleLegDrive(1, x, y, z, 20);
				IK_SingleLegDrive(2, x, y, z, 20);
				IK_SingleLegDrive(3, x, y, z, 20);
				IK_SingleLegDrive(4, x, y, z, 20);
				IK_SingleLegDrive(5, x, y, z, 20);
			}
			osDelay(1000);
/*
			for(y = 0 ; y <= 40 ; y+=5 )
			{
				IK_SingleLegDrive(0, x, Robot.LegPos.Init_Y+y, z, 20);
				IK_SingleLegDrive(1, x, Robot.LegPos.Init_Y+y, z, 20);
				IK_SingleLegDrive(2, x, Robot.LegPos.Init_Y+y, z, 20);
				IK_SingleLegDrive(3, x, Robot.LegPos.Init_Y-y, z, 20);
				IK_SingleLegDrive(4, x, Robot.LegPos.Init_Y-y, z, 20);
				IK_SingleLegDrive(5, x, Robot.LegPos.Init_Y-y, z, 20);
			}
			for(y = 0 ; y <= 40 ; y+=5 )
			{
				IK_SingleLegDrive(0, x, Robot.LegPos.Init_Y-y, z, 20);
				IK_SingleLegDrive(1, x, Robot.LegPos.Init_Y-y, z, 20);
				IK_SingleLegDrive(2, x, Robot.LegPos.Init_Y-y, z, 20);
				IK_SingleLegDrive(3, x, Robot.LegPos.Init_Y+y, z, 20);
				IK_SingleLegDrive(4, x, Robot.LegPos.Init_Y+y, z, 20);
				IK_SingleLegDrive(5, x, Robot.LegPos.Init_Y+y, z, 20);
			}
			for(y = 40 ; y >= 0 ; y-=5 )
			{
				IK_SingleLegDrive(0, x, Robot.LegPos.Init_Y-y, z, 20);
				IK_SingleLegDrive(1, x, Robot.LegPos.Init_Y-y, z, 20);
				IK_SingleLegDrive(2, x, Robot.LegPos.Init_Y-y, z, 20);
				IK_SingleLegDrive(3, x, Robot.LegPos.Init_Y+y, z, 20);
				IK_SingleLegDrive(4, x, Robot.LegPos.Init_Y+y, z, 20);
				IK_SingleLegDrive(5, x, Robot.LegPos.Init_Y+y, z, 20);
			}
			*/
/*
  			osDelay(1000);
			for(x = 0 ; x <= 30 ; x+=5 )
			{
				IK_SingleLegDrive(0, x, y, z, 20);
				IK_SingleLegDrive(1, x, y, z, 20);
				IK_SingleLegDrive(2, x, y, z, 20);
				IK_SingleLegDrive(3, x, y, z, 20);
				IK_SingleLegDrive(4, x, y, z, 20);
				IK_SingleLegDrive(5, x, y, z, 20);
			}
			for(x = 30 ; x >= -30 ; x-=5 )
			{
				IK_SingleLegDrive(0, x, y, z, 20);
				IK_SingleLegDrive(1, x, y, z, 20);
				IK_SingleLegDrive(2, x, y, z, 20);
				IK_SingleLegDrive(3, x, y, z, 20);
				IK_SingleLegDrive(4, x, y, z, 20);
				IK_SingleLegDrive(5, x, y, z, 20);
			}
			for(x = -30 ; x <= 0 ; x+=5 )
			{
				IK_SingleLegDrive(0, x, y, z, 20);
				IK_SingleLegDrive(1, x, y, z, 20);
				IK_SingleLegDrive(2, x, y, z, 20);
				IK_SingleLegDrive(3, x, y, z, 20);
				IK_SingleLegDrive(4, x, y, z, 20);
				IK_SingleLegDrive(5, x, y, z, 20);
			}
			osDelay(1000);
*/
			/*
			for(z = -100 ; z <= -20 ; z+=5 )
			{
				IK_SingleLegDrive(0, x, y, z, 20);
				IK_SingleLegDrive(1, x, y, z, 20);
				IK_SingleLegDrive(2, x, y, z, 20);
				IK_SingleLegDrive(3, x, y, z, 20);
				IK_SingleLegDrive(4, x, y, z, 20);
				IK_SingleLegDrive(5, x, y, z, 20);
			}
*/
			/*
			Eyes_SetExpression(Sad, fast);
			Ears_SetPosition(EarL_Down, EarR_Down, slow);
			osDelay(2000);
			Eyes_SetExpression(Neutral, fast);
			Ears_SetPosition(EarL_Middle, EarL_Middle, slow);
			osDelay(2000);
			Eyes_SetExpression(Furious, fast);
			Ears_SetPosition(EarL_Up, EarR_Up, slow);
			osDelay(2000);
			Eyes_SetExpression(Neutral, fast);
			Ears_SetPosition(EarL_Middle, EarL_Middle, slow);
			 */
			//NeckServos_Init();
		}
		else
		{

		}

		osDelay(125);
	}

}

void Board_PwrMngt(void)
{
	uint8_t i;

	if(Input.SIG_SYS == GPIO_PIN_RESET)
	{
		set_LED_ERR(ON);
		Board_Shutdown_ctr++;
	}
	else
	{
		set_LED_ERR(OFF);
		Board_Shutdown_ctr = 0;
	}

	if( (Board_Shutdown_ctr == 15) && (Robot.RPiState == RPi_OFF) )
	{
		for(i =0 ; i<10 ; i++)
		{
			set_LED_ERR(OFF);
			osDelay(50);
			set_LED_ERR(ON);
			osDelay(50);
		}

		BoardShutdownProcedure();
	}

}

void RPi_PwrMngt(void)
{
	uint16_t i, j;

	if( (Input.SW_PI_BOOT == GPIO_PIN_SET) && (Rpi_Shutdown_ctr < RPI_SHTDWN_MAX_TIMEOUT) )
	{
		Rpi_Shutdown_ctr++;
		//set_PI_SIG_ON(TRUE);
		set_PI_SIG_OFF(FALSE);
		set_RPI_PWR(ON);

		Robot.RPiState = RPi_ON;
	}
	else
	{
		Rpi_Shutdown_ctr=0;
	}

	if(Rpi_Shutdown_ctr == 1)
	{
		for(i=0 ; i<500 ; i++)
		{
			PWM_LED_PI = i;
			osDelay(3);
		}
	}

	if( (Rpi_Shutdown_ctr >= RPI_SHTDWN_MAX_TIMEOUT) /*&& (Input.RPI_RUNNING == GPIO_PIN_SET)*/ )
	{
		//set_RPI_PWR(FALSE);
		set_PI_SIG_OFF(TRUE);
		set_LED_ERR(ON);

		for(j=0 ; j<=3 ; j++)
		{
			PWM_LED_PI = 0;
			osDelay(50);
			PWM_LED_PI = 500;
			osDelay(50);
		}

		// Delay for the Rpi to shutdown (30ms x 500 = 15s)
		for(i=500 ; i>0 ; i--)
		{
			PWM_LED_PI = i;
			osDelay(30);
		}
		PWM_LED_PI = 0;

		set_LED_ERR(OFF);

		set_PI_SIG_OFF(FALSE);
		set_RPI_PWR(OFF);

		Robot.RPiState = RPi_OFF;

		Rpi_Shutdown_ctr = 0;
	}

}

void StartTask_FlexOled(void const * argument)
{
	uint8_t OLED_Ready = 0;

	osDelay(100);
	Flex_OLED_Init();
	Robot.OLED.OLED_Contrast = 50;
	Flex_OLED_setContrast(Robot.OLED.OLED_Contrast);
	OLED_Ready = Flex_OLED_StartupAnimation(5);
	osDelay(500);

	for(;;)
	{
		if( (OLED_Ready == OK) && (Input.SIG_SYS == GPIO_PIN_SET) )
		{
			switch(Flex_Oled_Menu)
			{
				case Battery:
					Flex_OLED_Menu_Battery();
				break;
				case Sensors:
					Flex_OLED_Menu_Sensors();
				break;
				case SPI_1:
					Flex_OLED_Menu_SPI1(&RPI_RxBuff, &RPI_TxBuff);
				break;
				case Modes:
					Flex_OLED_Menu_Modes();
				break;

				default:
				break;
			}
		}
		osDelay(100);
	}

}

void StartTask_Sensors(void const * argument)
{
	float Pitch, Roll;
	float rotX, rotY, rotZ;
	uint32_t val;
	float Temp_PSU = 0;
	float Temp_CHG = 0;
	float Temp_AVG = 0;
	uint16_t IR_Val;
	uint8_t IR_Dist;
	uint16_t LTC_VIN;

	osDelay(250);
	//I2C_Device_Check();

	LM75B_Init();
	ADC101_Init();
	LSM9DS1_Init();
	osDelay(100);

	for(;;)
	{
		LM75B_CHG_GetTemp(&Temp_CHG);
		LM75B_PSU_GetTemp(&Temp_PSU);
		Temp_AVG = (Temp_CHG + Temp_PSU)/2;
		ADC101_ReadIR(&IR_Val);
		LSM9DS1_ReadAngle(&Roll, &Pitch);
		//LSM9DS1_ReadGyro(&rotX, &rotY, &rotZ);

		Sensor.IMU.Pitch   	= Pitch;
		Sensor.IMU.Roll    	= Roll;
		Sensor.TempCharger 	= Temp_CHG;
		Sensor.TempPSU		= Temp_PSU;
		Sensor.TempAverage  = Temp_AVG;
		Sensor.dist_IR		= IR_Val;

		osDelay(50);
	}
}

void StartTask_Rpi(void const * argument)
{
	uint8_t aTxBuffer[16];
	uint8_t aRxBuffer[16];

	osDelay(1000);
	SPI1_init_IT();

	for(;;)
	{
		//HAL_SPI_TransmitReceive_IT(&hspi1, RPI_TxBuff, RPI_RxBuff, RPI_SPI_BUFF);

		if (Robot.RPiState == RPi_ON )
		{
			//ArUco markers
			if(RPI_RxBuff[0] == 0x01)
			{
				//             ID             dir_x          pixel_x,        dir_y         pixel_y        dist
				Tracking_ArUco(RPI_RxBuff[1], RPI_RxBuff[2], RPI_RxBuff[3], RPI_RxBuff[4], RPI_RxBuff[5], RPI_RxBuff[6]);
			}
		}
		osDelay(100);
		asm("NOP");
	}

}

void StartTask_Bluetooth(void const * argument)
{
	uint8_t header_master1[5U] = {0x0A, 0x00, 0x00, 0x00, 0x00};
	uint8_t header_master2[5U] = {0x0B, 0x00, 0x00, 0x00, 0x00};
	uint8_t header_slave[5U]  = {0x00, 0x00, 0x00, 0x00, 0x00};
	/*
	osDelay(1500);

	set_BT_RST(ON);
	osDelay(10);

	set_BT_CS(LOW);
	osDelay(1);
	//HAL_SPI_TransmitReceive(&hspi3, &header_master1, &header_slave, 5, 100);
	HAL_SPI_Transmit(&hspi3, &header_master2, 5, 100);
	HAL_SPI_Receive(&hspi3, &header_slave,5, 100);
	asm("NOP");
	HAL_SPI_TransmitReceive(&hspi3, &header_master2, &header_slave, 5, 100);
	asm("NOP");
	set_BT_CS(HIGH);
	asm("NOP");
 	*/

	for(;;)
	{

		osDelay(1000);
	}

}

void StartTask_Behavior(void const * argument)
{
	int8_t i=0,j=0;

	Robot.Eyes.Contrast = 50;

	osDelay(1500);
	Eyes_WakingUp(fast);
	Ears_SetPosition(EarL_Middle, EarR_Middle, verySlow);

	osDelay(1500);
	//Gaits_DefaultPosition(100);

	for(;;)
	{
		osDelay(7500);
		Eyes_Blink();
	}

}

void StartTask_Kinematic(void const * argument)
{

	osDelay(1000);
	//IK_LegInit();
	DRS0101_Clear(BROADCAST_ID);
	DRS0101_setTorque(BROADCAST_ID, TORQUE_ON);

	IK_StandbyPos(100);

	//Gaits_DefaultPosition(70);

	Robot.BodyCmd.TransX = 0;
	Robot.BodyCmd.TransY = 0;
	Robot.BodyCmd.TransZ = 0;
	Robot.BodyCmd.RotX	 = 0;
	Robot.BodyCmd.RotY	 = 0;
	Robot.BodyCmd.RotZ	 = 0;

	for(;;)
	{

		//IK_Run();
		osDelay(100);
	}

}

/*******************************************************************************************************************************************************/
/*******************************************************************************************************************************************************/
/*******************************************************************************************************************************************************/

// SPI first call occurs first, put 00 into the buffer until the host to take
void SPI1_init_IT(void)
{
	memset(RPI_TxBuff, 0xFF, RPI_SPI_BUFF);
	memset(RPI_RxBuff, 0xFF, RPI_SPI_BUFF);
	HAL_SPI_TransmitReceive_IT(&hspi1, RPI_TxBuff, RPI_RxBuff, RPI_SPI_BUFF);
}

void HAL_SPI_ErrorCallback(SPI_HandleTypeDef *hspi)
{
	if(hspi==&hspi1)
	{
		set_LED_ERR(ON);
		//BIP_3();
	}
}

void HAL_SPI_TxRxCpltCallback(SPI_HandleTypeDef *hspi)
{
	uint32_t i;

	if(hspi==&hspi1)
	{
		RPI_TxBuff[0] = 0x01+j;
		RPI_TxBuff[1] = 0x02+j;
		RPI_TxBuff[2] = 0x03+j;
		RPI_TxBuff[3] = 0x04+j;
		RPI_TxBuff[4] = 0x05+j;
		RPI_TxBuff[5] = 0x06+j;
		RPI_TxBuff[6] = 0x07+j;
		RPI_TxBuff[7] = 0x08+j;

		j++;
		//memset(RPI_RxBuff, 0xFF, RPI_SPI_BUFF);
		HAL_SPI_TransmitReceive_IT(&hspi1, RPI_TxBuff, RPI_RxBuff, RPI_SPI_BUFF);
		/*
		for(i=0; i<=1000000; i++)
		{
			asm("NOP");
		}
		*/
	}

}

void CheckInputs(void)
{
	Input.SW1 			= HAL_GPIO_ReadPin(GPIOA, GPIO_PIN_8);
	//Input.SW_HOOD		= HAL_GPIO_ReadPin(GPIOE, GPIO_PIN_15);
	Input.SW_OLED_MENU	= HAL_GPIO_ReadPin(GPIOE, GPIO_PIN_15);
	Input.SW_PI_BOOT	= HAL_GPIO_ReadPin(GPIOE, GPIO_PIN_14);
	Input.RPI_RUNNING   = HAL_GPIO_ReadPin(GPIOE, GPIO_PIN_9);
	Input.SIG_HOOD1		= HAL_GPIO_ReadPin(GPIOC, GPIO_PIN_8);
	Input.SIG_HOOD2		= HAL_GPIO_ReadPin(GPIOC, GPIO_PIN_9);
	Input.SIG_SYS		= HAL_GPIO_ReadPin(GPIOC, GPIO_PIN_5);
	Input.SIG_DOCK		= HAL_GPIO_ReadPin(GPIOD, GPIO_PIN_1);
	Input.CHARGER_FAULT = HAL_GPIO_ReadPin(GPIOC, GPIO_PIN_3);
	Input.PI_GPIO_B		= HAL_GPIO_ReadPin(GPIOE, GPIO_PIN_8);
}

void I2C_Device_Check(void)
{
	uint8_t addr, ctr, i, j;
	volatile uint8_t valid_addr[24];

	set_LED_B0(ON);

	for(j=0 ; j<24; j++)
	{
		valid_addr[j] = 0x00;
	}

	ctr = 0;
	addr= 0;

	HAL_I2C_DeInit(&hi2c2);
	HAL_Delay(10);
	HAL_I2C_Init(&hi2c2);
	HAL_Delay(10);

	for (addr=0 ; addr<=254 ; addr++)
	{
		if(HAL_I2C_IsDeviceReady(&hi2c2, addr, 5, 100) == HAL_OK)
		{
			valid_addr[ctr] = addr;
			ctr++;
		}
		HAL_Delay(10);
	}

	set_LED_B0(OFF);
}

/*******************************************************************************************************************************************************/
/*******************************************************************************************************************************************************/
/*******************************************************************************************************************************************************/

void _Error_Handler(char *file, int line)
{
	set_LED_ERR(ON);
	while(1)
	{

	}
}

/************************ (C) COPYRIGHT STMicroelectronics *****END OF FILE****/

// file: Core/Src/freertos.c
/**
  ******************************************************************************
  * File Name          : freertos.c
  * Description        : Code for freertos applications
  ******************************************************************************
  * This notice applies to any and all portions of this file
  * that are not between comment pairs USER CODE BEGIN and
  * USER CODE END. Other portions of this file, whether
  * inserted by the user or by software development tools
  * are owned by their respective copyright owners.
  *
  * Copyright (c) 2020 STMicroelectronics International N.V.
  * All rights reserved.
  *
  * Redistribution and use in source and binary forms, with or without
  * modification, are permitted, provided that the following conditions are met:
  *
  * 1. Redistribution of source code must retain the above copyright notice,
  *    this list of conditions and the following disclaimer.
  * 2. Redistributions in binary form must reproduce the above copyright notice,
  *    this list of conditions and the following disclaimer in the documentation
  *    and/or other materials provided with the distribution.
  * 3. Neither the name of STMicroelectronics nor the names of other
  *    contributors to this software may be used to endorse or promote products
  *    derived from this software without specific written permission.
  * 4. This software, including modifications and/or derivative works of this
  *    software, must execute solely and exclusively on microcontroller or
  *    microprocessor devices manufactured by or for STMicroelectronics.
  * 5. Redistribution and use of this software other than as permitted under
  *    this license is void and will automatically terminate your rights under
  *    this license.
  *
  * THIS SOFTWARE IS PROVIDED BY STMICROELECTRONICS AND CONTRIBUTORS "AS IS"
  * AND ANY EXPRESS, IMPLIED OR STATUTORY WARRANTIES, INCLUDING, BUT NOT
  * LIMITED TO, THE IMPLIED WARRANTIES OF MERCHANTABILITY, FITNESS FOR A
  * PARTICULAR PURPOSE AND NON-INFRINGEMENT OF THIRD PARTY INTELLECTUAL PROPERTY
  * RIGHTS ARE DISCLAIMED TO THE FULLEST EXTENT PERMITTED BY LAW. IN NO EVENT
  * SHALL STMICROELECTRONICS OR CONTRIBUTORS BE LIABLE FOR ANY DIRECT, INDIRECT,
  * INCIDENTAL, SPECIAL, EXEMPLARY, OR CONSEQUENTIAL DAMAGES (INCLUDING, BUT NOT
  * LIMITED TO, PROCUREMENT OF SUBSTITUTE GOODS OR SERVICES; LOSS OF USE, DATA,
  * OR PROFITS; OR BUSINESS INTERRUPTION) HOWEVER CAUSED AND ON ANY THEORY OF
  * LIABILITY, WHETHER IN CONTRACT, STRICT LIABILITY, OR TORT (INCLUDING
  * NEGLIGENCE OR OTHERWISE) ARISING IN ANY WAY OUT OF THE USE OF THIS SOFTWARE,
  * EVEN IF ADVISED OF THE POSSIBILITY OF SUCH DAMAGE.
  *
  ******************************************************************************
  */

#include "FreeRTOS.h"
#include "task.h"

/* Pre/Post sleep processing prototypes */
void PreSleepProcessing(uint32_t *ulExpectedIdleTime);
void PostSleepProcessing(uint32_t *ulExpectedIdleTime);

/* GetIdleTaskMemory prototype (linked to static allocation support) */
void vApplicationGetIdleTaskMemory( StaticTask_t **ppxIdleTaskTCBBuffer, StackType_t **ppxIdleTaskStackBuffer, uint32_t *pulIdleTaskStackSize );

/* Hook prototypes */
void configureTimerForRunTimeStats(void);
unsigned long getRunTimeCounterValue(void);

/* USER CODE BEGIN 1 */
/* Functions needed when configGENERATE_RUN_TIME_STATS is on */
__weak void configureTimerForRunTimeStats(void)
{

}

__weak unsigned long getRunTimeCounterValue(void)
{
return 0;
}
/* USER CODE END 1 */

/* USER CODE BEGIN PREPOSTSLEEP */
__weak void PreSleepProcessing(uint32_t *ulExpectedIdleTime)
{
/* place for user code */
}

__weak void PostSleepProcessing(uint32_t *ulExpectedIdleTime)
{
/* place for user code */
}
/* USER CODE END PREPOSTSLEEP */

/* USER CODE BEGIN GET_IDLE_TASK_MEMORY */
static StaticTask_t xIdleTaskTCBBuffer;
static StackType_t xIdleStack[configMINIMAL_STACK_SIZE];

void vApplicationGetIdleTaskMemory( StaticTask_t **ppxIdleTaskTCBBuffer, StackType_t **ppxIdleTaskStackBuffer, uint32_t *pulIdleTaskStackSize )
{
  *ppxIdleTaskTCBBuffer = &xIdleTaskTCBBuffer;
  *ppxIdleTaskStackBuffer = &xIdleStack[0];
  *pulIdleTaskStackSize = configMINIMAL_STACK_SIZE;
  /* place for user code */
}
/* USER CODE END GET_IDLE_TASK_MEMORY */

/************************ (C) COPYRIGHT STMicroelectronics *****END OF FILE****/
